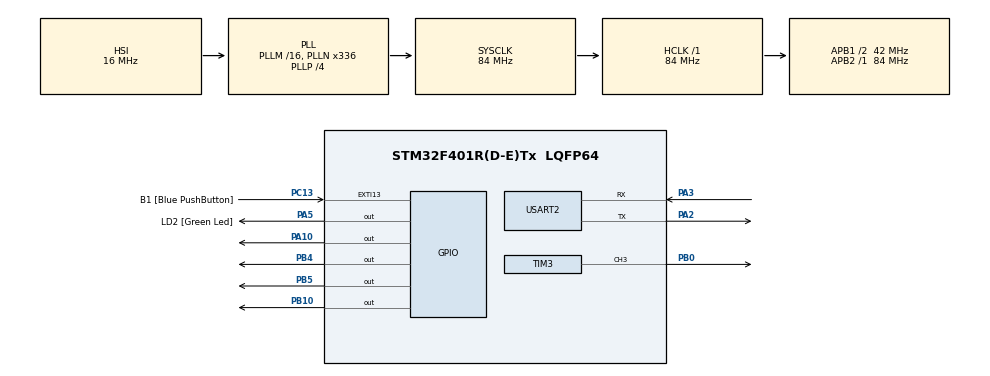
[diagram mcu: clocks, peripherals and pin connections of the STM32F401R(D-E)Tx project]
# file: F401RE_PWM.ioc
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Mcu.Family=STM32F4
Mcu.Name=STM32F401R(D-E)Tx
Mcu.Package=LQFP64
NVIC.PriorityGroup=NVIC_PRIORITYGROUP_0
PA10.Signal=GPIO_Output
PA13.GPIO_Label=TMS
PA13.Mode=Serial_Wire
PA13.Signal=SYS_JTMS-SWDIO
PA14.GPIO_Label=TCK
PA14.Mode=Serial_Wire
PA14.Signal=SYS_JTCK-SWCLK
PA2.Mode=Asynchronous
PA2.Signal=USART2_TX
PA3.Mode=Asynchronous
PA3.Signal=USART2_RX
PA5.GPIO_Label=LD2 [Green Led]
PA5.GPIO_Mode=GPIO_MODE_OUTPUT_PP
PA5.GPIO_PuPd=GPIO_NOPULL
PA5.GPIO_Speed=GPIO_SPEED_FREQ_LOW
PA5.Signal=GPIO_Output
PB0.Signal=S_TIM3_CH3
PB10.Signal=GPIO_Output
PB3.GPIO_Label=SWO
PB3.Signal=SYS_JTDO-SWO
PB4.Signal=GPIO_Output
PB5.Signal=GPIO_Output
PC13-ANTI_TAMP.GPIO_Label=B1 [Blue PushButton]
PC13-ANTI_TAMP.GPIO_ModeDefaultEXTI=GPIO_MODE_IT_FALLING
PC13-ANTI_TAMP.GPIO_PuPd=GPIO_NOPULL
PC13-ANTI_TAMP.Signal=GPXTI13
PC14-OSC32_IN.Mode=LSE-External-Oscillator
PC14-OSC32_IN.Signal=RCC_OSC32_IN
PC15-OSC32_OUT.Mode=LSE-External-Oscillator
PC15-OSC32_OUT.Signal=RCC_OSC32_OUT
PH0\ -\ OSC_IN.Mode=HSE-External-Clock-Source
PH0\ -\ OSC_IN.Signal=RCC_OSC_IN
PH1\ -\ OSC_OUT.Mode=HSE-External-Clock-Source
PH1\ -\ OSC_OUT.Signal=RCC_OSC_OUT
ProjectManager.HeapSize=0x200
ProjectManager.StackSize=0x400
ProjectManager.TargetToolchain=STM32CubeIDE
RCC.48MHZClocksFreq_Value=48000000
RCC.AHBFreq_Value=84000000
RCC.APB1CLKDivider=RCC_HCLK_DIV2
RCC.APB1Freq_Value=42000000
RCC.APB1TimFreq_Value=84000000
RCC.APB2Freq_Value=84000000
RCC.APB2TimFreq_Value=84000000
RCC.CortexFreq_Value=84000000
RCC.HCLKFreq_Value=84000000
RCC.HSE_VALUE=8000000
RCC.HSI_VALUE=16000000
RCC.PLLN=336
RCC.PLLP=RCC_PLLP_DIV4
RCC.PLLQ=7
RCC.SYSCLKFreq_VALUE=84000000
RCC.SYSCLKSource=RCC_SYSCLKSOURCE_PLLCLK
RCC.VCOOutputFreq_Value=336000000
SH.S_TIM3_CH3.0=TIM3_CH3,PWM Generation3 CH3
TIM3.Channel-PWM\ Generation3\ CH3=TIM_CHANNEL_3
TIM3.Period=100-1
TIM3.Prescaler=8400-1
TIM3.Pulse-PWM\ Generation3\ CH3=50-1
USART2.VirtualMode=VM_ASYNC
VP_TIM3_VS_ClockSourceINT.Mode=Internal
board=NUCLEO-F401RE

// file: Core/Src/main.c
/* USER CODE BEGIN Header */
/**
  ******************************************************************************
  * @file           : main.c
  * @brief          : Main program body
  ******************************************************************************
  * @attention
  *
  * Copyright (c) 2023 STMicroelectronics.
  * All rights reserved.
  *
  * This software is licensed under terms that can be found in the LICENSE file
  * in the root directory of this software component.
  * If no LICENSE file comes with this software, it is provided AS-IS.
  *
  ******************************************************************************
  */
/* USER CODE END Header */
#include "main.h"
#include "tim.h"
#include "usart.h"
#include "gpio.h"

void SystemClock_Config(void);

int main(void)
{

  /* MCU Configuration--------------------------------------------------------*/

  /* Reset of all peripherals, Initializes the Flash interface and the Systick. */
  HAL_Init();

  /* Configure the system clock */
  SystemClock_Config();

  /* Initialize all configured peripherals */
  MX_GPIO_Init();
  MX_USART2_UART_Init();
  MX_TIM3_Init();
  /* USER CODE BEGIN 2 */
  HAL_TIM_PWM_Start(&htim3, TIM_CHANNEL_3);   //타이머 PWM 초기화 함수
  uint16_t value = 0;
  /* USER CODE END 2 */

  /* Infinite loop */
  /* USER CODE BEGIN WHILE */
  while (1)
  {
	  TIM3 -> CCR3 = value;
	  // CCR3 레지스터는 PWM 타이머 모드에서 PWM 신호의 주기와 듀티 사이클을 조절하는 데 사용될 수 있습니다.
	  // CCR3 값을 변경하면 PWM 신호의 주기를 조정할 수 있으며, 이를 통해 모터 제어,
	  // LED 밝기 조절 등의 애플리케이션에서 사용됩니다.
	  value = value + 1;
	  // value+ = 1;
	  if(value > TIM3 -> ARR){
	  // ARR = Counter Period : 100-1로 설정 해놓음
		  value = 0;
	  }
	  HAL_Delay(100);
    /* USER CODE END WHILE */

  }
}

void SystemClock_Config(void)
{
  RCC_OscInitTypeDef RCC_OscInitStruct = {0};
  RCC_ClkInitTypeDef RCC_ClkInitStruct = {0};

  /** Configure the main internal regulator output voltage
  */
  __HAL_RCC_PWR_CLK_ENABLE();
  __HAL_PWR_VOLTAGESCALING_CONFIG(PWR_REGULATOR_VOLTAGE_SCALE2);

  /** Initializes the RCC Oscillators according to the specified parameters
  * in the RCC_OscInitTypeDef structure.
  */
  RCC_OscInitStruct.OscillatorType = RCC_OSCILLATORTYPE_HSI;
  RCC_OscInitStruct.HSIState = RCC_HSI_ON;
  RCC_OscInitStruct.HSICalibrationValue = RCC_HSICALIBRATION_DEFAULT;
  RCC_OscInitStruct.PLL.PLLState = RCC_PLL_ON;
  RCC_OscInitStruct.PLL.PLLSource = RCC_PLLSOURCE_HSI;
  RCC_OscInitStruct.PLL.PLLM = 16;
  RCC_OscInitStruct.PLL.PLLN = 336;
  RCC_OscInitStruct.PLL.PLLP = RCC_PLLP_DIV4;
  RCC_OscInitStruct.PLL.PLLQ = 7;
  if (HAL_RCC_OscConfig(&RCC_OscInitStruct) != HAL_OK)
  {
    Error_Handler();
  }

  /** Initializes the CPU, AHB and APB buses clocks
  */
  RCC_ClkInitStruct.ClockType = RCC_CLOCKTYPE_HCLK|RCC_CLOCKTYPE_SYSCLK
                              |RCC_CLOCKTYPE_PCLK1|RCC_CLOCKTYPE_PCLK2;
  RCC_ClkInitStruct.SYSCLKSource = RCC_SYSCLKSOURCE_PLLCLK;
  RCC_ClkInitStruct.AHBCLKDivider = RCC_SYSCLK_DIV1;
  RCC_ClkInitStruct.APB1CLKDivider = RCC_HCLK_DIV2;
  RCC_ClkInitStruct.APB2CLKDivider = RCC_HCLK_DIV1;

  if (HAL_RCC_ClockConfig(&RCC_ClkInitStruct, FLASH_LATENCY_2) != HAL_OK)
  {
    Error_Handler();
  }
}

void Error_Handler(void)
{
  __disable_irq();
  while (1)
  {
  }
}
